# iom480ae register map
Registers are 32-bit, access not given, no defined reset value unless marked. A register's access mark holds for its fields unless they carry their own. Addresses are absolute; registers are grouped by the start of their names; [hi:lo] are bit positions; {n}, {i} and the like mark numbered series; 'fields as' and 'values as' point back to an identical list.

## FMC
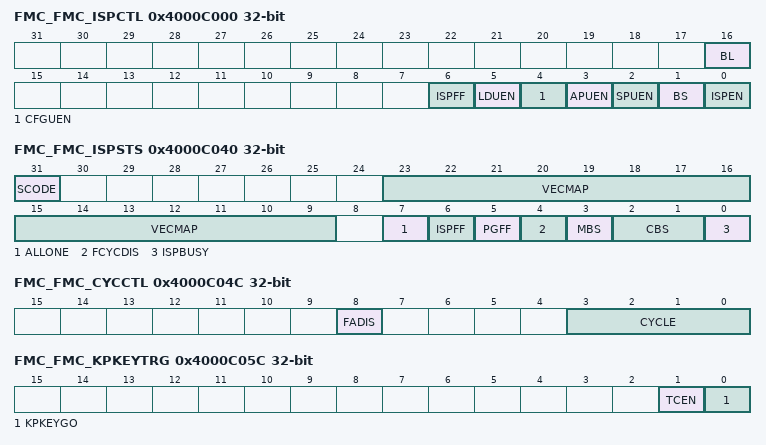
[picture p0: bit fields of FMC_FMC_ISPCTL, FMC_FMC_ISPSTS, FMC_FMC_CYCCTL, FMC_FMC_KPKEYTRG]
0x4000C000 FMC_FMC_ISPCTL
  [16] BL, [6] ISPFF, [5] LDUEN, [4] CFGUEN, [3] APUEN, [2] SPUEN, [1] BS, [0] ISPEN
0x4000C004 FMC_FMC_ISPADDR
0x4000C008 FMC_FMC_ISPDAT
0x4000C00C FMC_FMC_ISPCMD
  [6:0] CMD
0x4000C010 FMC_FMC_ISPTRG
  [0] ISPGO
0x4000C014 FMC_FMC_DFBA
0x4000C040 FMC_FMC_ISPSTS
  [31] SCODE, [23:9] VECMAP, [7] ALLONE, [6] ISPFF, [5] PGFF, [4] FCYCDIS, [3] MBS, [2:1] CBS, [0] ISPBUSY
0x4000C04C FMC_FMC_CYCCTL
  [8] FADIS, [3:0] CYCLE
{0x4000C050+4i} FMC_FMC_KPKEY{i} (i=0..2)
0x4000C05C FMC_FMC_KPKEYTRG
  [1] TCEN, [0] KPKEYGO
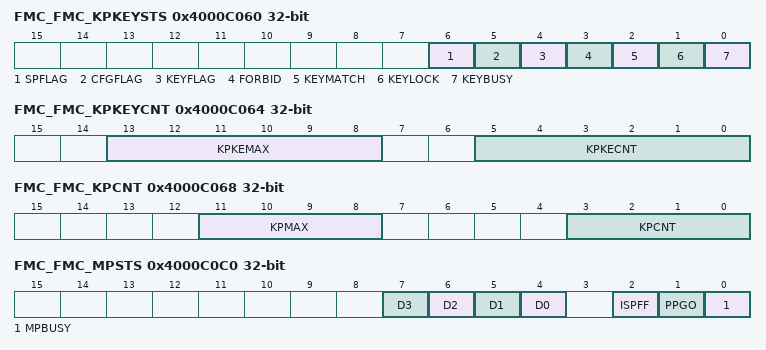
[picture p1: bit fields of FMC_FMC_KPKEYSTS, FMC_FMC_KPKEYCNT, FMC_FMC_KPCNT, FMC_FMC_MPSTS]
0x4000C060 FMC_FMC_KPKEYSTS
  [6] SPFLAG, [5] CFGFLAG, [4] KEYFLAG, [3] FORBID, [2] KEYMATCH, [1] KEYLOCK, [0] KEYBUSY
0x4000C064 FMC_FMC_KPKEYCNT
  [13:8] KPKEMAX, [5:0] KPKECNT
0x4000C068 FMC_FMC_KPCNT
  [11:8] KPMAX, [3:0] KPCNT
{0x4000C080+4i} FMC_FMC_MPDAT{i} (i=0..3)
0x4000C0C0 FMC_FMC_MPSTS
  [n+4] D{n} (n=0..3), [2] ISPFF, [1] PPGO, [0] MPBUSY
0x4000C0C4 FMC_FMC_MPADDR

## PDMA
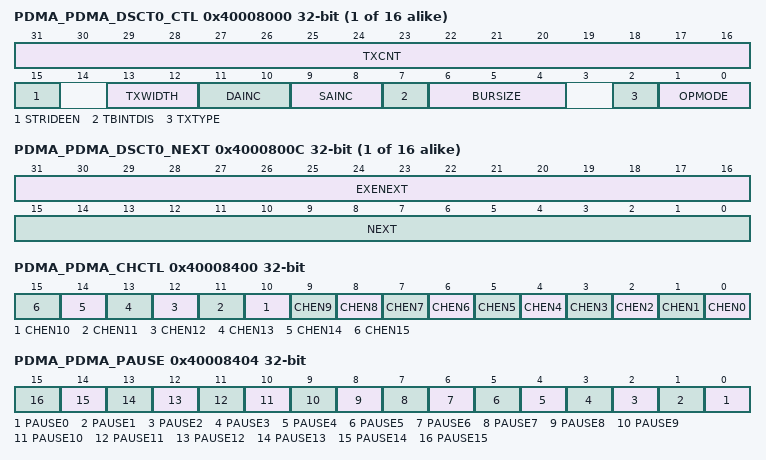
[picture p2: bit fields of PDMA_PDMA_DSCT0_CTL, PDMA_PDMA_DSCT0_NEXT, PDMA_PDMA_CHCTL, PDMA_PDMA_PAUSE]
{0x40008000+0x10*i} PDMA_PDMA_DSCT{i}_CTL (i=0..15)
  [31:16] TXCNT, [15] STRIDEEN, [13:12] TXWIDTH, [11:10] DAINC, [9:8] SAINC, [7] TBINTDIS, [6:4] BURSIZE, [2] TXTYPE, [1:0] OPMODE
{0x40008004+0x10*i} PDMA_PDMA_DSCT{i}_SA (i=0..15)
{0x40008008+0x10*i} PDMA_PDMA_DSCT{i}_DA (i=0..15)
{0x4000800C+0x10*i} PDMA_PDMA_DSCT{i}_NEXT (i=0..15)
  [31:16] EXENEXT, [15:0] NEXT
{0x40008100+4i} PDMA_PDMA_CURSCAT{i} (i=0..15)
0x40008400 PDMA_PDMA_CHCTL
  [n] CHEN{n} (n=0..15)
0x40008404 PDMA_PDMA_PAUSE
  [n] PAUSE{n} (n=0..15)
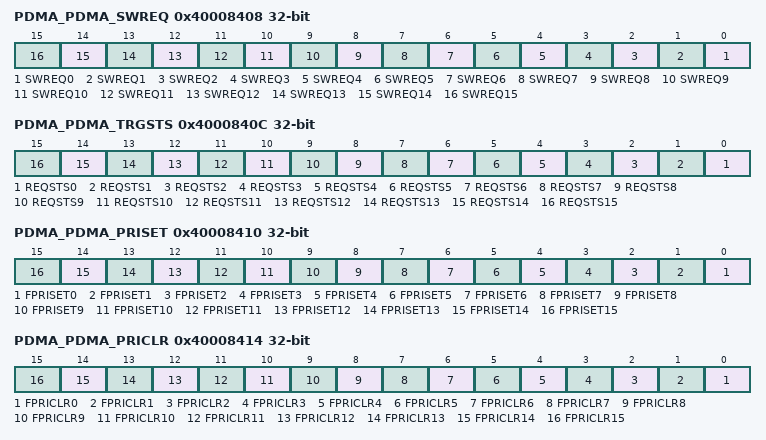
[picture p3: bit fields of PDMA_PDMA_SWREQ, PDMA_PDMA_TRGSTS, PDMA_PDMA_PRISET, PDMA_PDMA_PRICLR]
0x40008408 PDMA_PDMA_SWREQ
  [n] SWREQ{n} (n=0..15)
0x4000840C PDMA_PDMA_TRGSTS
  [n] REQSTS{n} (n=0..15)
0x40008410 PDMA_PDMA_PRISET
  [n] FPRISET{n} (n=0..15)
0x40008414 PDMA_PDMA_PRICLR
  [n] FPRICLR{n} (n=0..15)
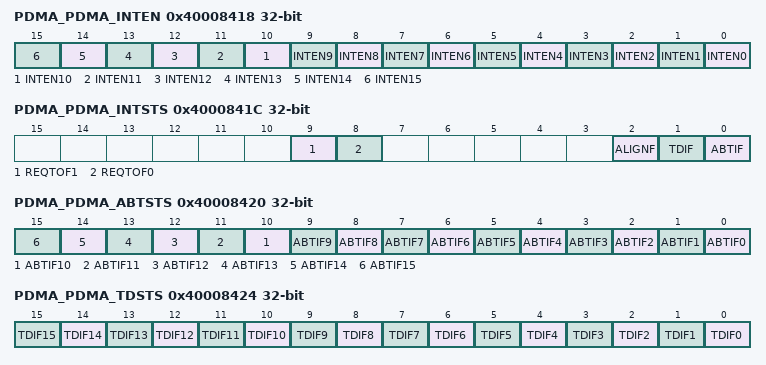
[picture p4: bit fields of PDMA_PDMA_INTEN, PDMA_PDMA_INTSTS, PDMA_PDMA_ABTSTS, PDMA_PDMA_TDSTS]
0x40008418 PDMA_PDMA_INTEN
  [n] INTEN{n} (n=0..15)
0x4000841C PDMA_PDMA_INTSTS
  [9] REQTOF1, [8] REQTOF0, [2] ALIGNF, [1] TDIF, [0] ABTIF
0x40008420 PDMA_PDMA_ABTSTS
  [n] ABTIF{n} (n=0..15)
0x40008424 PDMA_PDMA_TDSTS
  [n] TDIF{n} (n=0..15)
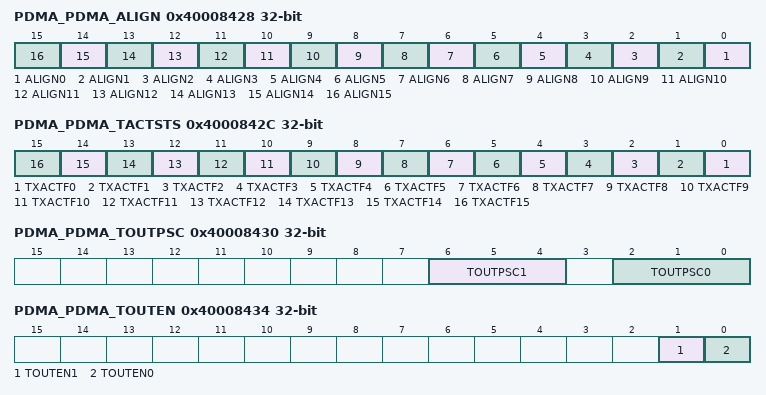
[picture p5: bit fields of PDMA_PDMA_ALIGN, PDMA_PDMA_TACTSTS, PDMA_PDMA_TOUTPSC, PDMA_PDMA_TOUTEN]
0x40008428 PDMA_PDMA_ALIGN
  [n] ALIGN{n} (n=0..15)
0x4000842C PDMA_PDMA_TACTSTS
  [n] TXACTF{n} (n=0..15)
0x40008430 PDMA_PDMA_TOUTPSC
  [6:4] TOUTPSC1, [2:0] TOUTPSC0
0x40008434 PDMA_PDMA_TOUTEN
  [1] TOUTEN1, [0] TOUTEN0
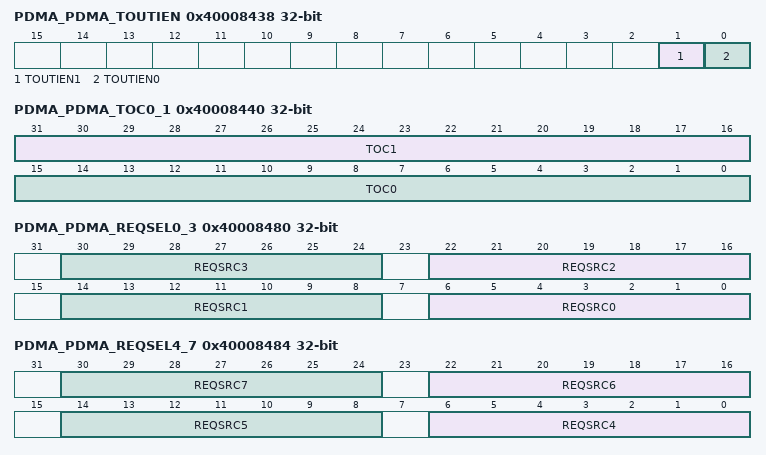
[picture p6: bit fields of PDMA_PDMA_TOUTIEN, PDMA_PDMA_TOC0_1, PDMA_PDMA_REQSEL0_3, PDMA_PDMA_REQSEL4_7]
0x40008438 PDMA_PDMA_TOUTIEN
  [1] TOUTIEN1, [0] TOUTIEN0
0x4000843C PDMA_PDMA_SCATBA
  [31:16] SCATBA
0x40008440 PDMA_PDMA_TOC0_1
  [31:16] TOC1, [15:0] TOC0
0x40008460 PDMA_PDMA_CHRST
  [15:0] CHnRST
0x40008464 PDMA_PDMA_SPI
0x40008480 PDMA_PDMA_REQSEL0_3
  [8n+6:8n] REQSRC{n} (n=0..3)
0x40008484 PDMA_PDMA_REQSEL4_7
  [8n-26:8n-32] REQSRC{n} (n=4..7)
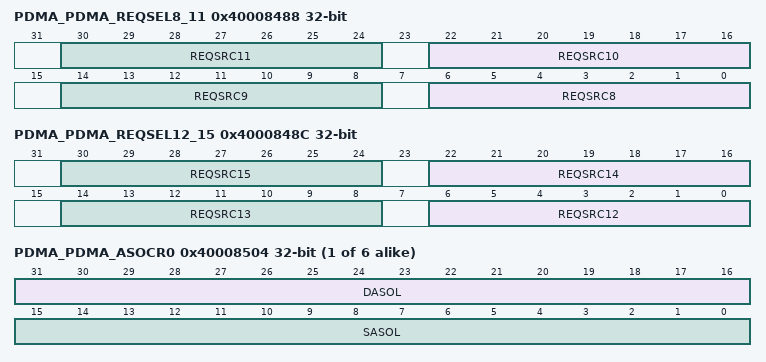
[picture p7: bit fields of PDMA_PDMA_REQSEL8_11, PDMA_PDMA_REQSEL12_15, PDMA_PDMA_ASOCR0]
0x40008488 PDMA_PDMA_REQSEL8_11
  [8n-58:8n-64] REQSRC{n} (n=8..11)
0x4000848C PDMA_PDMA_REQSEL12_15
  [8n-90:8n-96] REQSRC{n} (n=12..15)
{0x40008500+8i} PDMA_PDMA_STCR{i} (i=0..5)
  [15:0] STC
{0x40008504+8i} PDMA_PDMA_ASOCR{i} (i=0..5)
  [31:16] DASOL, [15:0] SASOL

## WDT
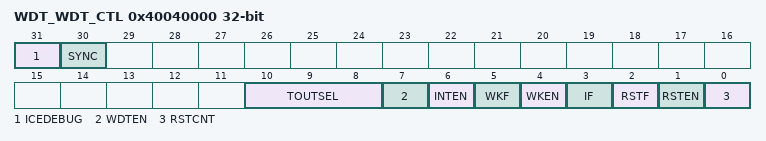
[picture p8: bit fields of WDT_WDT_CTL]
0x40040000 WDT_WDT_CTL
  [31] ICEDEBUG, [30] SYNC, [10:8] TOUTSEL, [7] WDTEN, [6] INTEN, [5] WKF, [4] WKEN, [3] IF, [2] RSTF, [1] RSTEN, [0] RSTCNT
0x40040004 WDT_WDT_ALTCTL
  [1:0] RSTDSEL
0x40040008 WDT_WDT_RSTCNT

## WWDT
0x40040100 WWDT_WWDT_RLDCNT
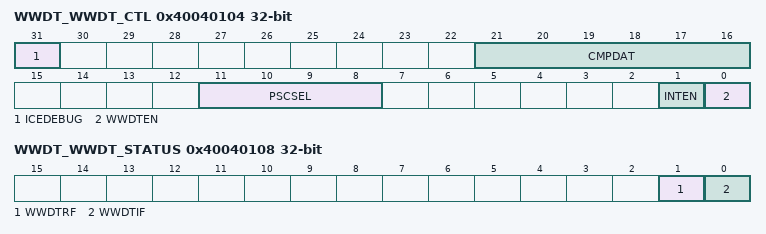
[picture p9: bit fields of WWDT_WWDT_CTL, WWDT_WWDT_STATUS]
0x40040104 WWDT_WWDT_CTL
  [31] ICEDEBUG, [21:16] CMPDAT, [11:8] PSCSEL, [1] INTEN, [0] WWDTEN
0x40040108 WWDT_WWDT_STATUS
  [1] WWDTRF, [0] WWDTIF
0x4004010C WWDT_WWDT_CNT
  [5:0] CNTDAT

## RTC
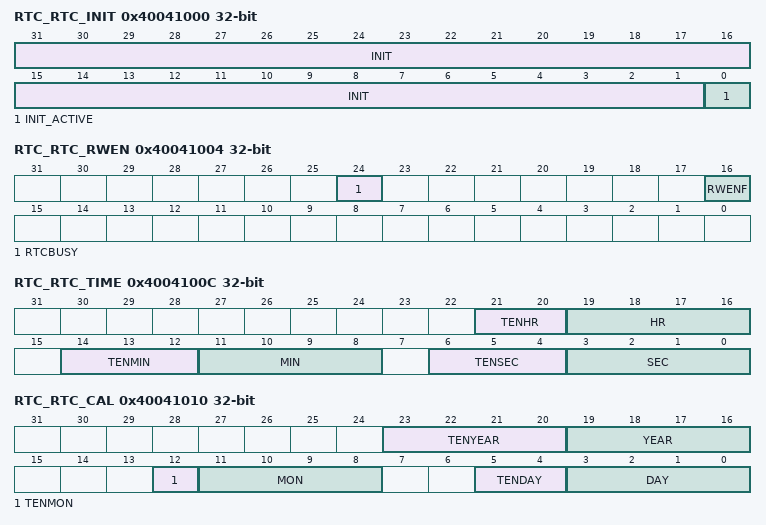
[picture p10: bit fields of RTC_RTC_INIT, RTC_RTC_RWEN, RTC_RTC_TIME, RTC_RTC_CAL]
0x40041000 RTC_RTC_INIT
  [31:1] INIT, [0] INIT_ACTIVE
0x40041004 RTC_RTC_RWEN
  [24] RTCBUSY, [16] RWENF
0x40041008 RTC_RTC_FREQADJ
  [21:0] FREQADJ
0x4004100C RTC_RTC_TIME
  [21:20] TENHR, [19:16] HR, [14:12] TENMIN, [11:8] MIN, [6:4] TENSEC, [3:0] SEC
0x40041010 RTC_RTC_CAL
  [23:20] TENYEAR, [19:16] YEAR, [12] TENMON, [11:8] MON, [5:4] TENDAY, [3:0] DAY
0x40041014 RTC_RTC_CLKFMT
  [0] 24HEN
0x40041018 RTC_RTC_WEEKDAY
  [2:0] WEEKDAY
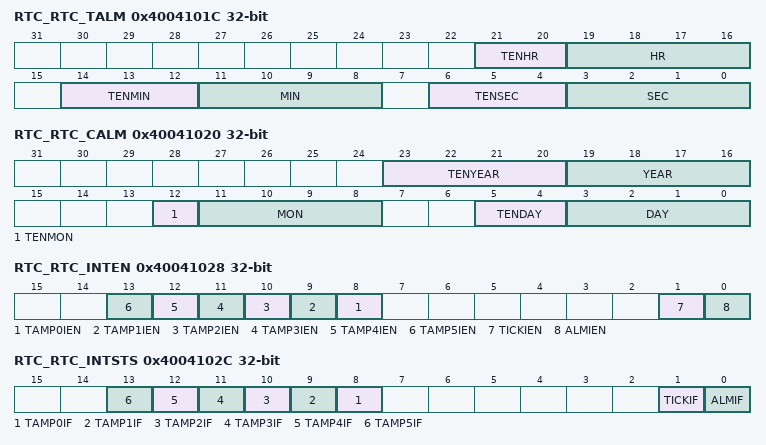
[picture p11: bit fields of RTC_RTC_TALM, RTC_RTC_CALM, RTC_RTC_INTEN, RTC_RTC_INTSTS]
0x4004101C RTC_RTC_TALM
  fields as RTC_RTC_TIME
0x40041020 RTC_RTC_CALM
  fields as RTC_RTC_CAL
0x40041024 RTC_RTC_LEAPYEAR
  [0] LEAPYEAR
0x40041028 RTC_RTC_INTEN
  [n+8] TAMP{n}IEN (n=0..5), [1] TICKIEN, [0] ALMIEN
0x4004102C RTC_RTC_INTSTS
  [n+8] TAMP{n}IF (n=0..5), [1] TICKIF, [0] ALMIF
0x40041030 RTC_RTC_TICK
  [2:0] TICK
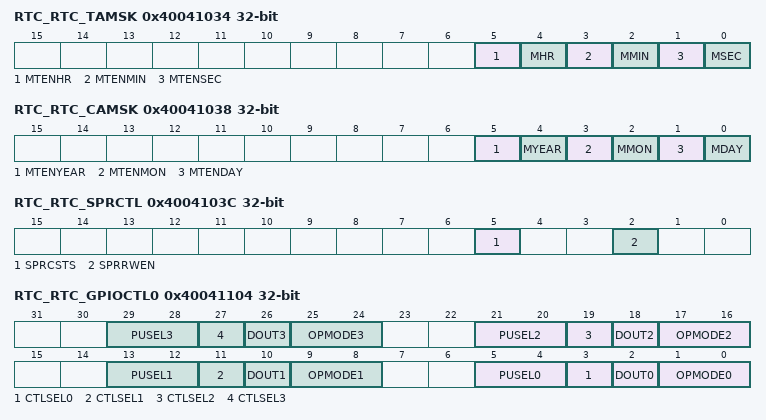
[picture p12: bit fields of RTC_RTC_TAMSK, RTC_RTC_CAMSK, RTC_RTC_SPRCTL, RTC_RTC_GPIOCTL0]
0x40041034 RTC_RTC_TAMSK
  [5] MTENHR, [4] MHR, [3] MTENMIN, [2] MMIN, [1] MTENSEC, [0] MSEC
0x40041038 RTC_RTC_CAMSK
  [5] MTENYEAR, [4] MYEAR, [3] MTENMON, [2] MMON, [1] MTENDAY, [0] MDAY
0x4004103C RTC_RTC_SPRCTL
  [5] SPRCSTS, [2] SPRRWEN
{0x40041040+4i} RTC_RTC_SPR{i} (i=0..19)
0x40041100 RTC_RTC_LXTCTL
  [2:1] GAIN
0x40041104 RTC_RTC_GPIOCTL0
  [8n+5:8n+4] PUSEL{n} (n=0..3), [8n+3] CTLSEL{n} (n=0..3), [8n+2] DOUT{n} (n=0..3), [8n+1:8n] OPMODE{n} (n=0..3)
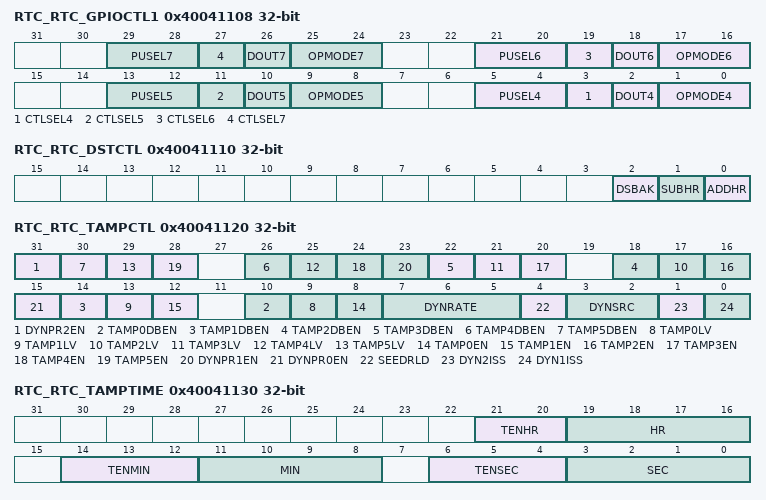
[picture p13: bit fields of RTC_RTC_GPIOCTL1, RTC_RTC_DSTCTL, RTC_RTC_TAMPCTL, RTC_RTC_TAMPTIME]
0x40041108 RTC_RTC_GPIOCTL1
  [8n-27:8n-28] PUSEL{n} (n=4..7), [8n-29] CTLSEL{n} (n=4..7), [8n-30] DOUT{n} (n=4..7), [8n-31:8n-32] OPMODE{n} (n=4..7)
0x40041110 RTC_RTC_DSTCTL
  [2] DSBAK, [1] SUBHR, [0] ADDHR
0x40041120 RTC_RTC_TAMPCTL
  [31] DYNPR2EN, [4n+10] TAMP{n}DBEN (n=0..5), [4n+9] TAMP{n}LV (n=0..5), [4n+8] TAMP{n}EN (n=0..5), [23] DYNPR1EN, [15] DYNPR0EN, [7:5] DYNRATE, [4] SEEDRLD, [3:2] DYNSRC, [1] DYN2ISS, [0] DYN1ISS
0x40041128 RTC_RTC_TAMPSEED
0x40041130 RTC_RTC_TAMPTIME
  fields as RTC_RTC_TIME
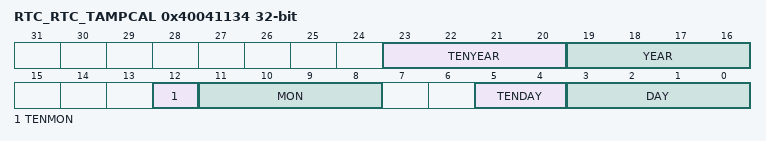
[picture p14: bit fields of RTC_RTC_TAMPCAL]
0x40041134 RTC_RTC_TAMPCAL
  fields as RTC_RTC_CAL
